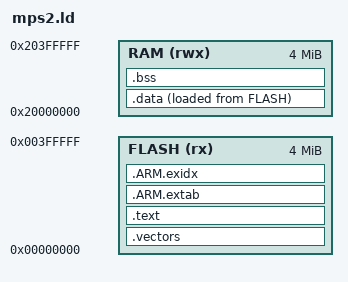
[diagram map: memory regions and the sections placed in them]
ENTRY(Reset_Handler)
MEMORY
{
    FLASH (rx) : ORIGIN = 0x00000000, LENGTH = 4M
    RAM (rwx) : ORIGIN = 0x20000000, LENGTH = 4M
}
_estack = ORIGIN(RAM) + LENGTH(RAM);
SECTIONS
{
    .vectors : { KEEP(*(.vectors)) } > FLASH
    .text : { *(.text*) *(.rodata*) } > FLASH
    .ARM.extab : { *(.ARM.extab*) } > FLASH
    .ARM.exidx : {
        __exidx_start = .;
        *(.ARM.exidx*)
        __exidx_end = .;
    } > FLASH
    .data : {
        . = ALIGN(4);
        _sdata = .;
        *(.data*)
        . = ALIGN(4);
        _edata = .;
    } > RAM AT > FLASH
    _sidata = LOADADDR(.data);
    .bss (NOLOAD) : {
        . = ALIGN(4);
        _sbss = .;
        *(.bss*) *(COMMON)
        . = ALIGN(4);
        _ebss = .;
    } > RAM
    _end = .;
    /DISCARD/ : { *(.comment*) *(.note*) }
}
